# MSP430G2X53 register map
Vendor: msp430gen; File version: v0.4.0-16-g4f822b9
Registers are 8-bit, read-write, reset 0x0 unless marked. A register's access mark holds for its fields unless they carry their own. Offsets are from the block's base; [hi:lo] are bit positions; {n}, {i} and the like mark numbered series.

## COMPARATOR_A
Base 0x00000058
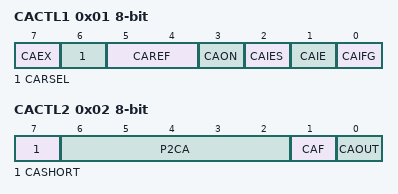
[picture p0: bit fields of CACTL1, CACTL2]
0x01 CACTL1 — Comparator A Control 1
  [7] CAEX — Comp. A Exchange Inputs
  [6] CARSEL — Comp. A Internal Reference Enable
  [5:4] CAREF — Comp. A Internal Reference Select 0
    0=Comp. A Int. Ref. Select 0 : Off; 1=Comp. A Int. Ref. Select 1 : 0.25*Vcc; 2=Comp. A Int. Ref. Select 2 : 0.5*Vcc; 3=Comp. A Int. Ref. Select 3 : Vt
  [3] CAON — Comp. A enable
  [2] CAIES — Comp. A Int. Edge Select: 0:rising / 1:falling
  [1] CAIE — Comp. A Interrupt Enable
  [0] CAIFG — Comp. A Interrupt Flag
0x02 CACTL2 — Comparator A Control 2
  [7] CASHORT — Comp. A Short + and - Terminals
  [6:2] P2CA — Comp. A +Terminal Multiplexer
    0=NONE_NONE (No + or - connection); 1=CA0_NONE (Connect + to CA0, no connection to -); 2=NONE_CA1 (No connection to +, connect - to CA1); 3=CA0_CA1 (Connect + to CA0, connect - to CA1); 4=NONE_CA2 (No connection to +, connect - to CA2); 5=CA0_CA2 (Connect + to CA0, connect - to CA2); 6=NONE_CA3 (No connection to +, connect - to CA3); 7=CA0_CA3 (Connect + to CA0, connect - to CA3); 8=NONE_CA4 (No connection to +, connect - to CA4); 9=CA0_CA4 (Connect + to CA0, connect - to CA4); 10=NONE_CA5 (No connection to +, connect - to CA5); 11=CA0_CA5 (Connect + to CA0, connect - to CA5); 12=NONE_CA6 (No connection to +, connect - to CA6); 13=CA0_CA6 (Connect + to CA0, connect - to CA6); 14=NONE_CA7 (No connection to +, connect - to CA7); 15=CA0_CA7 (Connect + to CA0, connect - to CA7); 16=CA1_NONE (Connect + to CA1, no connection to -); 17=CA2_NONE (Connect + to CA2, no connection to -); 18=CA1_CA1 (Connect + to CA1, connect - to CA1); 19=CA2_CA1 (Connect + to CA2, connect - to CA1); 20=CA1_CA2 (Connect + to CA1, connect - to CA2); 21=CA2_CA2 (Connect + to CA2, connect - to CA2); 22=CA1_CA3 (Connect + to CA1, connect - to CA3); 23=CA2_CA3 (Connect + to CA2, connect - to CA3); 24=CA1_CA4 (Connect + to CA1, connect - to CA4); 25=CA2_CA4 (Connect + to CA2, connect - to CA4); 26=CA1_CA5 (Connect + to CA1, connect - to CA5); 27=CA2_CA5 (Connect + to CA2, connect - to CA5); 28=CA1_CA6 (Connect + to CA1, connect - to CA6); 29=CA2_CA6 (Connect + to CA2, connect - to CA6); 30=CA1_CA7 (Connect + to CA1, connect - to CA7); 31=CA2_CA7 (Connect + to CA2, connect - to CA7)
  [1] CAF — Comp. A Enable Output Filter
  [0] CAOUT — Comp. A Output
0x03 CAPD — Comparator A Port Disable
  [7] CAPD7 — Comp. A Disable Input Buffer of Port Register .7
  [6] CAPD6 — Comp. A Disable Input Buffer of Port Register .6
  [5] CAPD5 — Comp. A Disable Input Buffer of Port Register .5
  [4] CAPD4 — Comp. A Disable Input Buffer of Port Register .4
  [3] CAPD3 — Comp. A Disable Input Buffer of Port Register .3
  [2] CAPD2 — Comp. A Disable Input Buffer of Port Register .2
  [1] CAPD1 — Comp. A Disable Input Buffer of Port Register .1
  [0] CAPD0 — Comp. A Disable Input Buffer of Port Register .0
  [7:0] CAPD — Comparator A Port Disable register

## USCI_A0_UART_MODE
Base 0x0000005C
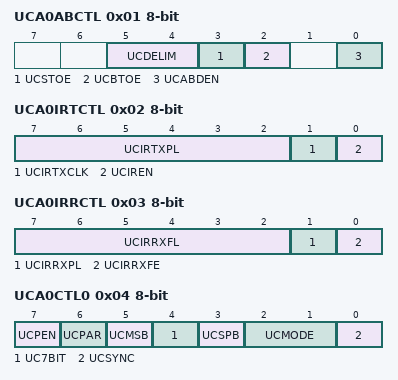
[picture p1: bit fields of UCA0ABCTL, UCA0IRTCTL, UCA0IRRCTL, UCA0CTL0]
0x01 UCA0ABCTL — USCI A0 LIN Control
  [5:4] UCDELIM — Break Sync Delimiter 0
  [3] UCSTOE — Sync-Field Timeout error
  [2] UCBTOE — Break Timeout error
  [0] UCABDEN — Auto Baud Rate detect enable
0x02 UCA0IRTCTL — USCI A0 IrDA Transmit Control
  [7:2] UCIRTXPL — IRDA Transmit Pulse Length 0
  [1] UCIRTXCLK — IRDA Transmit Pulse Clock Select
  [0] UCIREN — IRDA Encoder/Decoder enable
0x03 UCA0IRRCTL — USCI A0 IrDA Receive Control
  [7:2] UCIRRXFL — IRDA Receive Filter Length 0
  [1] UCIRRXPL — IRDA Receive Input Polarity
  [0] UCIRRXFE — IRDA Receive Filter enable
0x04 UCA0CTL0 — USCI A0 Control Register 0
  [7] UCPEN — Async. Mode: Parity enable
  [6] UCPAR — Async. Mode: Parity 0:odd / 1:even
  [5] UCMSB — Async. Mode: MSB first 0:LSB / 1:MSB
  [4] UC7BIT — Async. Mode: Data Bits 0:8-bits / 1:7-bits
  [3] UCSPB — Async. Mode: Stop Bits 0:one / 1: two
  [2:1] UCMODE — Async. Mode: USCI Mode 1
    {v}=Sync. Mode: USCI Mode: {v} (v=0..3)
  [0] UCSYNC — Sync-Mode 0:UART-Mode / 1:SPI-Mode
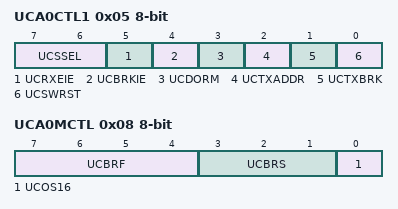
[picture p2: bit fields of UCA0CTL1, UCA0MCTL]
0x05 UCA0CTL1 — USCI A0 Control Register 1
  [7:6] UCSSEL — USCI 0 Clock Source Select 1
    {v}=USCI 0 Clock Source: {v} (v=0..3)
  [5] UCRXEIE — RX Error interrupt enable
  [4] UCBRKIE — Break interrupt enable
  [3] UCDORM — Dormant (Sleep) Mode
  [2] UCTXADDR — Send next Data as Address
  [1] UCTXBRK — Send next Data as Break
  [0] UCSWRST — USCI Software Reset
0x06 UCA0BR0 — USCI A0 Baud Rate 0
  [7:0] UCA0BR0 — USCI A0 Baud Rate 0 register
0x07 UCA0BR1 — USCI A0 Baud Rate 1
  [7:0] UCA0BR1 — USCI A0 Baud Rate 1 register
0x08 UCA0MCTL — USCI A0 Modulation Control
  [7:4] UCBRF — USCI First Stage Modulation Select 3
    {v}=USCI First Stage Modulation: {v} (v=0..9); 10=USCI First Stage Modulation: A; 11=USCI First Stage Modulation: B; 12=USCI First Stage Modulation: C; 13=USCI First Stage Modulation: D; 14=USCI First Stage Modulation: E; 15=USCI First Stage Modulation: F
  [3:1] UCBRS — USCI Second Stage Modulation Select 2
    {v}=USCI Second Stage Modulation: {v} (v=0..7)
  [0] UCOS16 — USCI 16-times Oversampling enable
0x09 UCA0STAT — USCI A0 Status Register
  [7] UCLISTEN — USCI Listen mode
  [6] UCFE — USCI Frame Error Flag
  [5] UCOE — USCI Overrun Error Flag
  [4] UCPE — USCI Parity Error Flag
  [3] UCBRK — USCI Break received
  [2] UCRXERR — USCI RX Error Flag
  [1] UCADDR — USCI Address received Flag
  [1] UCIDLE — Idle line detected
  [0] UCBUSY — USCI Busy Flag
0x0A UCA0RXBUF — USCI A0 Receive Buffer
  [7:0] UCA0RXBUF — USCI A0 Receive Buffer register
0x0B UCA0TXBUF — USCI A0 Transmit Buffer
  [7:0] UCA0TXBUF — USCI A0 Transmit Buffer register
